# netx90_app register map
File version: 1.0
CPU: CM4 r0p1, little endian, MPU, FPU, 4 interrupt priority bits, 78 interrupts
Registers are 32-bit, read-write, reset 0x0 unless marked. A register's access mark holds for its fields unless they carry their own. Offsets are from the block's base; [hi:lo] are bit positions; {n}, {i} and the like mark numbered series; 'fields as' and 'values as' point back to an identical list.

## can_ctrl0_app
Base 0xFF801200
Same registers: can_ctrl1_app 0xFF801280
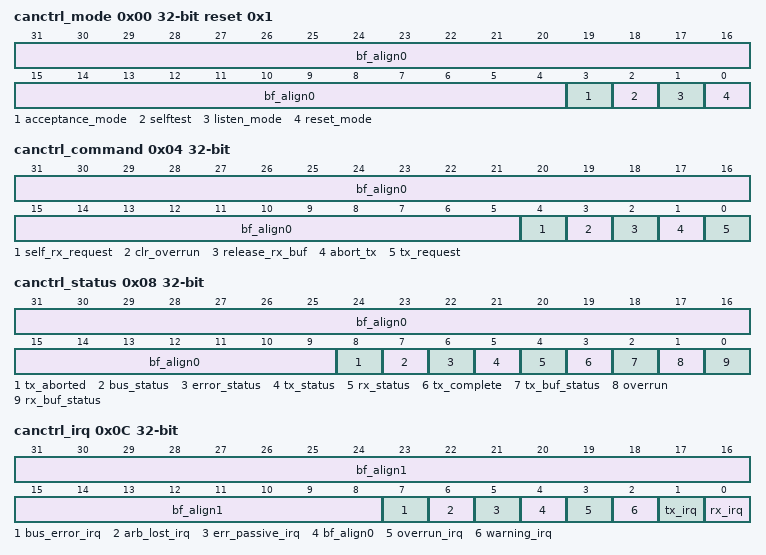
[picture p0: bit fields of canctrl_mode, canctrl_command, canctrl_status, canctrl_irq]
0x00 canctrl_mode reset 0x1 (reset mask 0xF) — CAN mode register
  [31:4] bf_align0 — bitField alignment value for aeabi compatibility
  [3] acceptance_mode — Acceptance Filter Mode 1 single; the single acceptance filter option is enabled (one filter with the length of 32 bit is active) 0 dual; the dual acceptance filter option is enabled (two filters, each with the length of 16 bit are active)
  [2] selftest — Self Test Mode 1 self test; in this mode a full node test is possible without any other active node on the bus using the self reception request command; the CAN controller will perform a successful transmission, even if there is no acknowledge received 0 normal; an acknowledge is required for successful transmission
  [1] listen_mode — Listen Only Mode 1 listen only; in this mode the CAN controller would give no acknowledge to the CAN-bus, even if a message is received successfully; the error counters are stopped at the current value 0 normal
  [0] reset_mode — Reset Mode 1 reset; detection of a set reset mode bit results in aborting the current transmission/reception of a message and entering the reset mode 0 normal; on the `1-to-0' transition of the reset mode bit, the CAN controller returns to the operating mode
0x04 canctrl_command wo (reset mask 0x1F) — CAN command register
  [31:5] bf_align0 — bitField alignment value for aeabi compatibility
  [4] self_rx_request — Self Reception Request, self-clearing 1 present; a message shall be transmitted and received simultaneously Setting tx_request and self_rx_request simultaneously will ignore the set self_rx_request bit.
  [3] clr_overrun — Clear Data Overrun, self-clearing 1 clear; the data overrun status bit is cleared, shall be used together with release_rx_buf to release invalid buffer
  [2] release_rx_buf — Release Receive Buffer, self-clearing 1 released; the receive buffer, representing the message memory space in the RXFIFO is released
  [1] abort_tx — Abort Transmission, self-clearing 1 present; if not already in progress, a pending transmission request is cancelled Setting the command bits tx_request and abort_tx simultaneously results in sending the transmit message once. No re-transmission will be performed in the event of an error or arbitration lost (single-shot transmission).
  [0] tx_request — Transmission Request, self-clearing 1 present; a message shall be transmitted
0x08 canctrl_status ro (reset mask 0x1FF) — CAN status register
  [31:9] bf_align0 — bitField alignment value for aeabi compatibility
  [8] tx_aborted — Transmission aborted 1 Previously requested transmission is aborted
  [7] bus_status — Bus Status 1 bus-off; the CAN controller is not involved in bus activities 0 bus-on; the CAN controller is involved in bus activities
  [6] error_status — Error Status 1 error; at least one of the error counters has reached or exceeded the CPU warning limit defined by the Error Warning Limit Register (EWLR) 0 ok; both error counters are below the warning limit
  [5] tx_status — Transmit Status 1 transmit; the CAN controller is transmitting a message 0 idle
  [4] rx_status — Receive Status 1 receive; the CAN controller is receiving a message 0 idle
  [3] tx_complete — Transmission Complete 1 complete; last requested transmission has been successfully completed 0 incomplete; previously requested transmission is not yet completed
  [2] tx_buf_status — Transmit Buffer Status 1 released; the CPU may write a message into the transmit buffer 0 locked; the CPU cannot access the transmit buffer ; a message is either waiting for transmission or is in the process of being transmitted
  [1] overrun — Data Overrun Status 1 overrun; a message was lost because there was not enough space for that message in the RXFIFO 0 absent; no data overrun has occurred since the last clear data overrun command was given
  [0] rx_buf_status — Receive Buffer Status 1 full; one or more complete messages are available in the RXFIFO 0 empty; no message is available
0x0C canctrl_irq ro (reset mask 0xEF) — CAN interrupt register reading the register will clear all bits except rx_irq
  [31:8] bf_align1 — bitField alignment value for aeabi compatibility
  [7] bus_error_irq — Bus Error Interrupt 1 set; this bit is set when the CAN controller detects an error on the CAN-bus and the bus_error_irq_en bit is set within the interrupt enable register, will only get active again if canctrl_err_code_capture register is read 0 reset
  [6] arb_lost_irq — Arbitration Lost Interrupt 1 set; this bit is set when the CAN controller lost the arbitration and becomes a receiver and the arb_lost_irq_en bit is set within the interrupt enable register, will only get active again if canctrl_arb_lost_capture register is read 0 reset
  [5] err_passive_irq — Error Passive Interrupt 1 set; this bit is set whenever the CAN controller has reached the error passive status (at least one error counter exceeds the protocol-defined level of 127) or if the CAN controller is in the error passive status and enters the error active status again and the err_passive_irq_en bit is set within the interrupt enable register 0 reset
  [4] bf_align0 — bitField alignment value for aeabi compatibility
  [3] overrun_irq — Data Overrun Interrup 1 set; this bit is set on a `0-to-1' transition of the data overrun status bit and the overrun_irq_en bit is set within the interrupt enable register 0 reset
  [2] warning_irq — Error Warning Interrupt 1 set; this bit is set on every change (set and clear) of either the error status or bus status bits and the warning_irq_en bit is set within the interrupt enable register 0 reset
  [1] tx_irq — Transmit Interrupt 1 set; this bit is set whenever the transmit buffer status changes from `0-to-1' (released) and the tx_irq_en bit is set within the interrupt enable register 0 reset
  [0] rx_irq — Receive Interrupt 1 set; this bit is set while the receive FIFO is not empty and the rx_irq_en bit is set within the interrupt enable register 0 reset; no more message is available within the RXFIFO
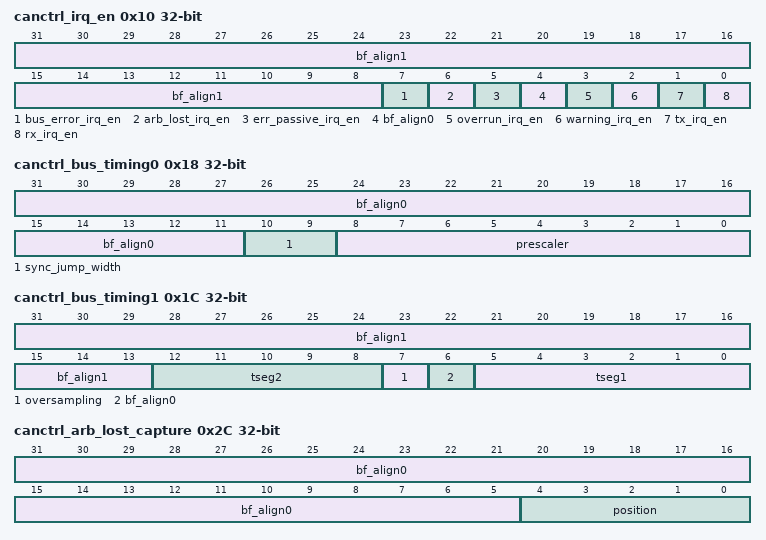
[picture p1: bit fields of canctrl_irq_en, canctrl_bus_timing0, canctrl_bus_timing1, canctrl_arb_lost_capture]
0x10 canctrl_irq_en (reset mask 0xEF) — CAN interrupt enable register in not extended mode: acceptance_code_0
  [31:8] bf_align1 — bitField alignment value for aeabi compatibility
  [7] bus_error_irq_en — Bus Error Interrupt Enable 1 enabled; if an bus error has been detected, the CAN controller requests the respective interrupt 0 disabled
  [6] arb_lost_irq_en — Arbitration Lost Interrupt Enable 1 enabled; if the CAN controller has lost arbitration, the respective interrupt is requested 0 disabled
  [5] err_passive_irq_en — Error Passive Interrupt Enable 1 enabled; if the error status of the CAN controller changes from error active to error passive or vice versa, the respective interrupt is requested 0 disabled
  [4] bf_align0 — bitField alignment value for aeabi compatibility
  [3] overrun_irq_en — Data Overrun Interrupt Enable 1 enabled; if the data overrun status bit is set (see status register; Table 14), the CAN controller requests the respective interrupt 0 disabled
  [2] warning_irq_en — Error Warning Interrupt Enable 1 enabled; if the error or bus status change (see status register), the CAN controller requests the respective interrupt 0 disabled
  [1] tx_irq_en — Transmit Interrupt Enable 1 enabled; when a message has been successfully transmitted or the transmit buffer is accessible again (e.g. after an abort transmission command), the CAN controller requests the respective interrupt 0 disabled
  [0] rx_irq_en — Receive Interrupt Enable 1 enabled; when the receive buffer status is `full' the CAN controller requests the respective interrupt 0 disabled
0x14 canctrl_not_extended_acceptance_mask0 reset not defined — CAN not extended acceptance mask register
  [31:0] bf_align0 — bitField alignment value for aeabi compatibility
0x18 canctrl_bus_timing0 (reset mask 0x7FF) — CAN bus timing register 0, only writable in reset mode in not extended mode: acceptance_mask_0
  [31:11] bf_align0 — bitField alignment value for aeabi compatibility
  [10:9] sync_jump_width — Synchronization Jump Width To compensate for phase shifts between clock oscillators of different bus controllers, any bus controller must re-synchronize on any relevant signal edge of the current transmission. The synchronization jump width defines the maximum number of clock cycles a bit period may be shortened or lengthened by one re-synchronization: tSJW = tscl * (sync_jump_width + 1)
  [8:0] prescaler — Baud Rate Prescaler The period of the CAN system clock tscl is programmable and determines the individual bit timing. The CAN system clock is calculated using the following equation: tscl = tCLK * prescaler with tCLK = 10 ns
0x1C canctrl_bus_timing1 (reset mask 0x1FBF) — CAN bus timing register 1, only writable in reset mode
  [31:13] bf_align1 — bitField alignment value for aeabi compatibility
  [12:8] tseg2 — Time Segment 2 (TSEG2) TSEG2 determine the number of clock cycles per bit period and the location of the sample point, where: tTSEG2 = tscl * (tseg2 + 1)
  [7] oversampling — Sampling 1 triple; the bus is sampled three times; recommended for low/medium speed buses (class A and B) where filtering spikes on the bus line is beneficial 0 single; the bus is sampled once; recommended for high speed buses (SAE class C)
  [6] bf_align0 — bitField alignment value for aeabi compatibility
  [5:0] tseg1 — Time Segment 1 (TSEG1) TSEG1 determine the number of clock cycles per bit period and the location of the sample point, where: tSYNCSEG = 1 * tscl tTSEG1 = tscl * (tseg1 + 1)
0x28 canctrl_not_extended_data0 reset not defined — CAN not extended data register
  [31:0] bf_align0 — bitField alignment value for aeabi compatibility
0x2C canctrl_arb_lost_capture ro (reset mask 0x1F) — CAN arbitration lost capture register This register contains information about the bit position of losing arbitration. reading the register will clear all bits in not extended mode: data1
  [31:5] bf_align0 — bitField alignment value for aeabi compatibility
  [4:0] position — Positon where arbitration was lost { | Decimal value Position 00 arbitration lost in bit 1 of identifier 01 arbitration lost in bit 2 of identifier 02 arbitration lost in bit 3 of identifier 03 arbitration lost in bit 4 of identifier 04 arbitration lost in bit 5 of identifier 05 arbitration lost in bit 6 of identifier 06 arbitration lost in bit 7 of identifier 07 arbitration lost in bit 8 of identifier 08 arbitration lost in bit 9 of identifier 09 arbitration lost in bit 10 of identifier 10 arbitration lost in bit 11 of identifier 11 arbitration lost in bit SRTR; (bit RTR for standard frame messages) 12 arbitration lost in bit IDE 13 arbitration lost in bit 12 of identifier; extended frame messages only 14 arbitration lost in bit 13 of identifier; extended frame messages only 15 arbitration lost in bit 14 of identifier; extended frame messages only 16 arbitration lost in bit 15 of identifier; extended frame messages only 17 arbitration lost in bit 16 of identifier; extended frame messages only 18 arbitration lost in bit 17 of identifier; extended frame messages only 19 arbitration lost in bit 18 of identifier; extended frame messages only 20 arbitration lost in bit 19 of identifier; extended frame messages only 21 arbitration lost in bit 20 of identifier; extended frame messages only 22 arbitration lost in bit 21 of identifier; extended frame messages only 23 arbitration lost in bit 22 of identifier; extended frame messages only 24 arbitration lost in bit 23 of identifier; extended frame messages only 25 arbitration lost in bit 24 of identifier; extended frame messages only 26 arbitration lost in bit 25 of identifier; extended frame messages only 27 arbitration lost in bit 26 of identifier; extended frame messages only 28 arbitration lost in bit 27 of identifier; extended frame messages only 29 arbitration lost in bit 28 of identifier; extended frame messages only 30 arbitration lost in bit 29 of identifier; extended frame messages only 31 arbitration lost in bit RTR; extended frame messages only }
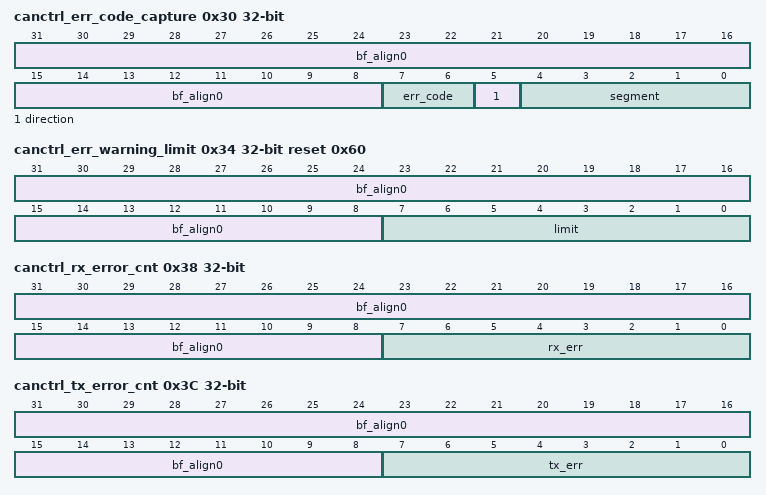
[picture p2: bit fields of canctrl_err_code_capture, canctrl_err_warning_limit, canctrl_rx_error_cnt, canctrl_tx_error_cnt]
0x30 canctrl_err_code_capture ro (reset mask 0xFF) — CAN error code capture register This register contains information about the type and location of errors on the bus. reading the register will clear all bits in not extended mode: data2
  [31:8] bf_align0 — bitField alignment value for aeabi compatibility
  [7:6] err_code — Error code { | Binary value Code 00 bit error 01 form error 10 stuff error 11 other type of error }
  [5] direction — Direction 1 RX; error occurred during reception 0 TX; error occurred during transmission
  [4:0] segment — Frame segment where error was detected { | Binary value Segment 00011 start of frame 00010 ID.28 to ID.21 00110 ID.20 to ID.18 00100 bit SRTR 00101 bit IDE 00111 ID.17 to ID.13 01111 ID.12 to ID.5 01110 ID.4 to ID.0 01100 bit RTR 01101 reser ved bit 1 01001 reser ved bit 0 01011 data length code 01010 data field 01000 CRC sequence 11000 CRC delimiter 11001 acknowledge slot 11011 acknowledge delimiter 11010 end of frame 10010 intermission 10001 active error flag 10110 passive error flag 10011 tolerate dominant bits 10111 error delimiter 11100 overload flag }
0x34 canctrl_err_warning_limit reset 0x60 (reset mask 0xFF) — CAN error warning limit register, only writable in reset mode in not extended mode: data3
  [31:8] bf_align0 — bitField alignment value for aeabi compatibility
  [7:0] limit — error warning limit
0x38 canctrl_rx_error_cnt (reset mask 0xFF) — CAN RX error counter register, only writable in reset mode The RX error counter register reflects the current value of the receive error counter. If a bus-off event occurs, the RX error counter is initialized to logic 0. The time bus-off is valid, writing to this register has no effect. Note, that a CPU-forced content change of the RX error counter is only possible, if the reset mode was entered previously. An error status change (see status register), an error warning or an error passive interrupt forced by the new register content will not occur, until the reset mode is cancelled again. in not extended mode: data4
  [31:8] bf_align0 — bitField alignment value for aeabi compatibility
  [7:0] rx_err — rx error counter
0x3C canctrl_tx_error_cnt (reset mask 0xFF) — CAN TX error counter register, only writable in reset mode The TX error counter register reflects the current value of the transmit error counter. If a bus-off event occurs, the TX error counter is initialized to 127 to count the minimum protocol-defined time (128 occurrences of the bus-free signal). Reading the TX error counter during this time gives information about the status of the bus-off recovery. If bus-off is active, a write access to TXERR in the range from 0 to 254 clears the bus-off flag and the controller will wait for one occurrence of 11 consecutive recessive bits (bus-free) after the reset mode has been cleared. Writing 255 to TXERR allows to initiate a CPU-driven bus-off event. It should be noted that a CPU-forced content change of the TX error counter is only possible, if the reset mode was entered previously. An error or bus status change (see status register), an error warning or an error passive interrupt forced by the new register content will not occur until the reset mode is cancelled again. After leaving the reset mode, the new TX counter content is interpreted and the bus-off event is performed in the same way, as if it was forced by a bus error event. That means, that the reset mode is entered again, the TX error counter is initialized to 127, the RX counter is cleared and all concerned status and interrupt register bits are set. Clearing of reset mode now will perform the protocol-defined bus-off recovery sequence (waiting for 128 occurrences of the bus-free signal). If the reset mode is entered again before the end of bus-off recovery (TXERR > 0), bus-off keeps active and TXERR is frozen. in not extended mode: data5
  [31:8] bf_align0 — bitField alignment value for aeabi compatibility
  [7:0] tx_err — tx error counter
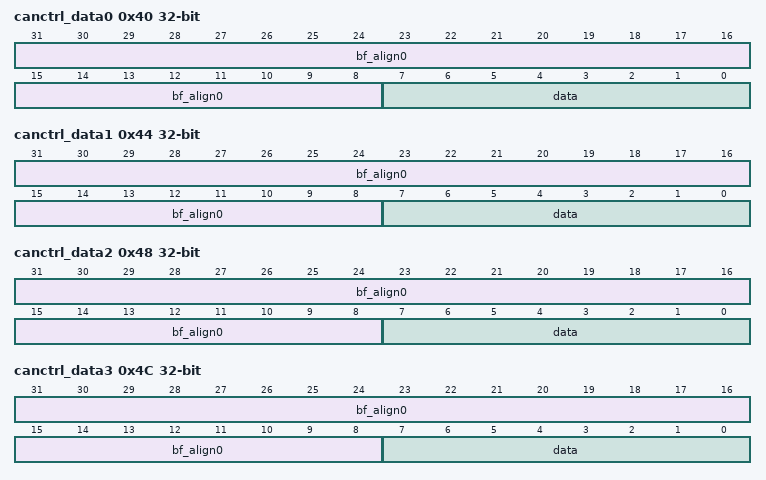
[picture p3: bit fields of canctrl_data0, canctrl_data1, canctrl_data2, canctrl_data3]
0x40 canctrl_data0 (reset mask 0xFF) — CAN data register 0 This register has multiple functions depending on reset mode and read or write access. { | | Reset mode: R/W: Read or write acceptance code 0 Operating mode: R: Standard frame: Read RX frame information Extended frame: Read RX frame information W: Standard frame: Write TX frame information Extended frame: Write TX frame information } in not extended mode: data6
  [31:8] bf_align0 — bitField alignment value for aeabi compatibility
  [7:0] data — register content (rx data, tx data or acceptance code)
0x44 canctrl_data1 (reset mask 0xFF) — CAN data register 1 This register has multiple functions depending on reset mode and read or write access. { | | Reset mode: R/W: Read or write acceptance code 1 Operating mode: R: Standard frame: Read RX identifier 1 Extended frame: Read RX identifier 1 W: Standard frame: Write TX identifier 1 Extended frame: Write TX identifier 1 } in not extended mode: data7
  fields as canctrl_data0
0x48 canctrl_data2 (reset mask 0xFF) — CAN data register 2 This register has multiple functions depending on reset mode and read or write access. { | | Reset mode: R/W: Read or write acceptance code 2 Operating mode: R: Standard frame: Read RX identifier 2 Extended frame: Read RX identifier 2 W: Standard frame: Write TX identifier 2 Extended frame: Write TX identifier 2 } in not extended mode: data8
  fields as canctrl_data0
0x4C canctrl_data3 (reset mask 0xFF) — CAN data register 3 This register has multiple functions depending on reset mode and read or write access. { | | Reset mode: R/W: Read or write acceptance code 3 Operating mode: R: Standard frame: Read RX data 1 Extended frame: Read RX identifier 3 W: Standard frame: Write TX data 1 Extended frame: Write TX identifier 3 } in not extended mode: data9
  fields as canctrl_data0
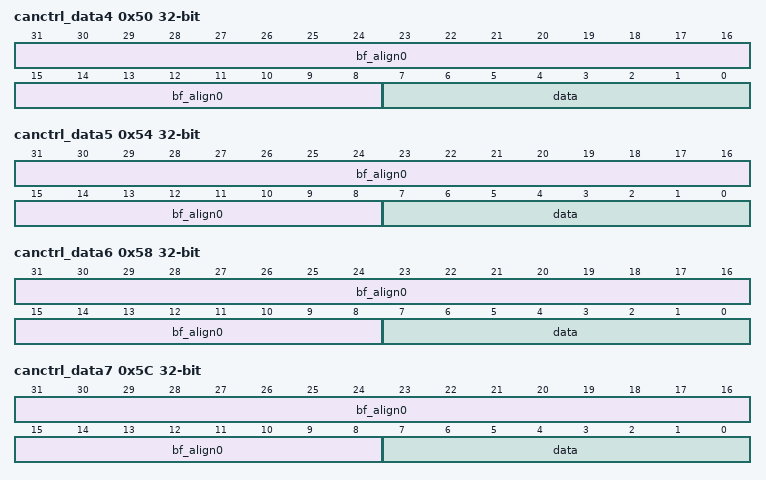
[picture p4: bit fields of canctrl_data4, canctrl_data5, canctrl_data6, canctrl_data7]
0x50 canctrl_data4 (reset mask 0xFF) — CAN data register 4 This register has multiple functions depending on reset mode and read or write access. { | | Reset mode: R/W: Read or write acceptance mask 0 Operating mode: R: Standard frame: Read RX data 2 Extended frame: Read RX identifier 4 W: Standard frame: Write TX data 2 Extended frame: Write TX identifier 4 }
  [31:8] bf_align0 — bitField alignment value for aeabi compatibility
  [7:0] data — register content (rx data, tx data or acceptance mask)
0x54 canctrl_data5 (reset mask 0xFF) — CAN data register 5 This register has multiple functions depending on reset mode and read or write access. { | | Reset mode: R/W: Read or write acceptance mask 1 Operating mode: R: Standard frame: Read RX data 3 Extended frame: Read RX data 1 W: Standard frame: Write TX data 3 Extended frame: Write TX data 1 }
  fields as canctrl_data4
0x58 canctrl_data6 (reset mask 0xFF) — CAN data register 6 This register has multiple functions depending on reset mode and read or write access. { | | Reset mode: R/W: Read or write acceptance mask 2 Operating mode: R: Standard frame: Read RX data 4 Extended frame: Read RX data 2 W: Standard frame: Write TX data 4 Extended frame: Write TX data 2 }
  fields as canctrl_data4
0x5C canctrl_data7 (reset mask 0xFF) — CAN data register 7 This register has multiple functions depending on reset mode and read or write access. { | | Reset mode: R/W: Read or write acceptance mask 3 Operating mode: R: Standard frame: Read RX data 5 Extended frame: Read RX data 3 W: Standard frame: Write TX data 5 Extended frame: Write TX data 3 }
  fields as canctrl_data4
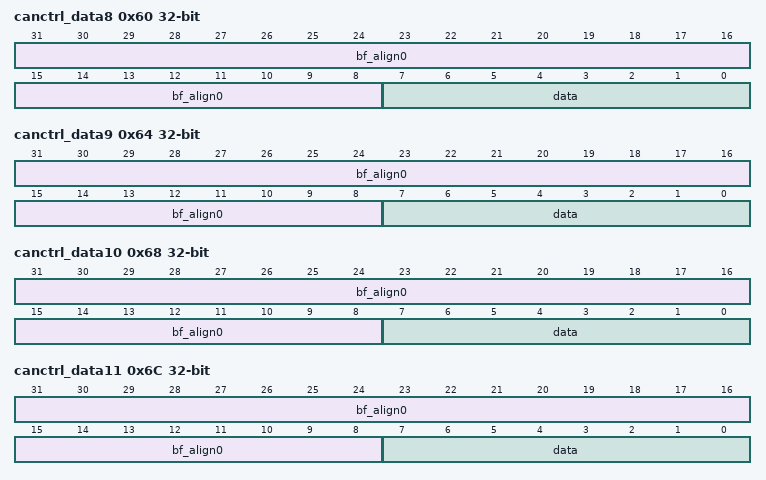
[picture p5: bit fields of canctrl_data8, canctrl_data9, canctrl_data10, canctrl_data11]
0x60 canctrl_data8 (reset mask 0xFF) — CAN data register 8 This register has multiple functions depending on reset mode and read or write access. { | | Reset mode: R/W: reserved Operating mode: R: Standard frame: Read RX data 6 Extended frame: Read RX data 4 W: Standard frame: Write TX data 6 Extended frame: Write TX data 4 }
  [31:8] bf_align0 — bitField alignment value for aeabi compatibility
  [7:0] data — register content (rx data or tx data)
0x64 canctrl_data9 (reset mask 0xFF) — CAN data register 9 This register has multiple functions depending on reset mode and read or write access. { | | Reset mode: R/W: reserved Operating mode: R: Standard frame: Read RX data 7 Extended frame: Read RX data 5 W: Standard frame: Write TX data 7 Extended frame: Write TX data 5 }
  fields as canctrl_data8
0x68 canctrl_data10 (reset mask 0xFF) — CAN data register 10 This register has multiple functions depending on reset mode and read or write access. { | | Reset mode: R/W: reserved Operating mode: R: Standard frame: Read RX data 8 Extended frame: Read RX data 6 W: Standard frame: Write TX data 8 Extended frame: Write TX data 6 }
  fields as canctrl_data8
0x6C canctrl_data11 (reset mask 0xFF) — CAN data register 11 This register has multiple functions depending on reset mode and read or write access. { | | Reset mode: R/W: reserved Operating mode: R: Standard frame: reserved Extended frame: Read RX data 7 W: Standard frame: reserved Extended frame: Write TX data 7 }
  fields as canctrl_data8
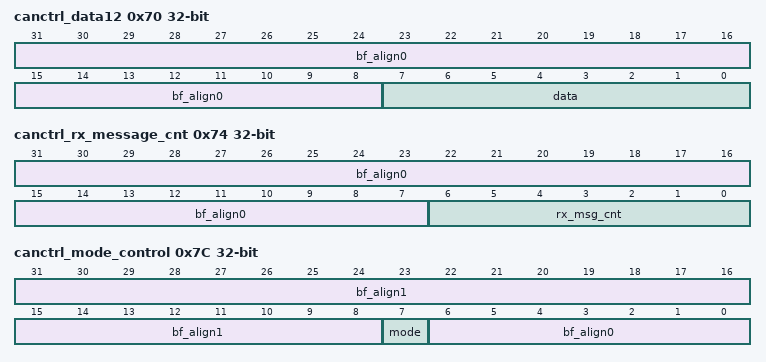
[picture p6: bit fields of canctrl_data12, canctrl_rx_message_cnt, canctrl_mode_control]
0x70 canctrl_data12 (reset mask 0xFF) — CAN data register 12 This register has multiple functions depending on reset mode and read or write access. { | | Reset mode: R/W: reserved Operating mode: R: Standard frame: reserved Extended frame: Read RX data 8 W: Standard frame: reserved Extended frame: Write TX data 8 }
  fields as canctrl_data8
0x74 canctrl_rx_message_cnt ro (reset mask 0x7F) — CAN RX message counter register Reflects the number of messages available within the RXFIFO. The value is incremented with each receive event and decremented by the release receive buffer command. After any reset event, this register is cleared.
  [31:7] bf_align0 — bitField alignment value for aeabi compatibility
  [6:0] rx_msg_cnt — rx message counter
0x7C canctrl_mode_control ro (reset mask 0x80) — CAN mode control register, only writable in reset mode
  [31:8] bf_align1 — bitField alignment value for aeabi compatibility
  [7] mode — 0: BasicCAN mode, 1: PeliCAN mode recommended value is 1 (PeliCAN mode), The here given register map of all registers of the CAN controller is valid for PeliCAN only.
  [6:0] bf_align0 — bitField alignment value for aeabi compatibility
